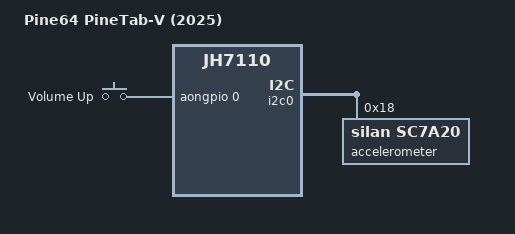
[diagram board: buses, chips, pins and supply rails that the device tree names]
// SPDX-License-Identifier: GPL-2.0 OR MIT
/*
 * Copyright (C) 2022 StarFive Technology Co., Ltd.
 * Copyright (C) 2022 Hal Feng <hal.feng@starfivetech.com>
 * Copyright (C) 2025 Icenowy Zheng <uwu@icenowy.me>
 */

/dts-v1/;
#include "jh7110-pine64-pinetabv.dtsi"

/ {
	model = "Pine64 PineTab-V (2025)";
	compatible = "pine64,pinetabv-2025", "pine64,pinetabv", "starfive,jh7110";
};

&gpio_keys {
	key-vol-up {
		debounce-interval = <10>;
		gpios = <&aongpio 0 GPIO_ACTIVE_HIGH>;
		label = "Volume Up";
		linux,input-type = <EV_KEY>;
		linux,code = <KEY_VOLUMEUP>;
	};
};

&i2c0 {
	accelerometer@18 {
		compatible = "silan,sc7a20";
		reg = <0x18>;
		mount-matrix = "0",  "0", "-1",
			       "1",  "0",  "0",
			       "0", "-1",  "0";
	};
};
